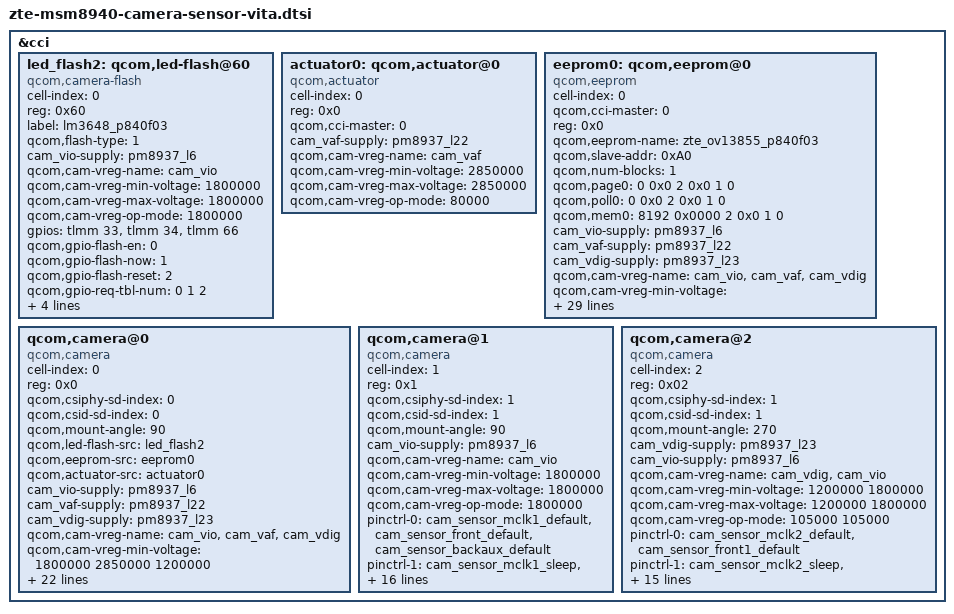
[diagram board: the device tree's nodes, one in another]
/*
 * Copyright (c) 2015-2017, The Linux Foundation. All rights reserved.
 *
 * This program is free software; you can redistribute it and/or modify
 * it under the terms of the GNU General Public License version 2 and
 * only version 2 as published by the Free Software Foundation.
 *
 * This program is distributed in the hope that it will be useful,
 * but WITHOUT ANY WARRANTY; without even the implied warranty of
 * MERCHANTABILITY or FITNESS FOR A PARTICULAR PURPOSE.  See the
 * GNU General Public License for more details.
 */


&cci {
	led_flash2: qcom,led-flash@60{
		cell-index = <0>;
		compatible = "qcom,camera-flash";
		reg = <0x60>;
		label = "lm3648_p840f03";
		qcom,flash-type = <1>;
		cam_vio-supply = <&pm8937_l6>;
		qcom,cam-vreg-name = "cam_vio";
		qcom,cam-vreg-min-voltage = <1800000>;
		qcom,cam-vreg-max-voltage = <1800000>;
		qcom,cam-vreg-op-mode = <1800000>;
		gpios = <&tlmm 33 0>,
			<&tlmm 34 0>,
			<&tlmm 66 0>;
		qcom,gpio-flash-en = <0>;
		qcom,gpio-flash-now = <1>;
		qcom,gpio-flash-reset = <2>;
		qcom,gpio-req-tbl-num = <0 1 2>;
		qcom,gpio-req-tbl-flags = <0 0 0>;
		qcom,gpio-req-tbl-label = "FLASH_EN",
			"FLASH_NOW",
			"FLASH_RESET";
		qcom,cci-master = <0>;
	};
	actuator0: qcom,actuator@0 {
		cell-index = <0>;
		reg = <0x0>;
		compatible = "qcom,actuator";
		qcom,cci-master = <0>;
		cam_vaf-supply = <&pm8937_l22>;
		qcom,cam-vreg-name = "cam_vaf";
		qcom,cam-vreg-min-voltage = <2850000>;
		qcom,cam-vreg-max-voltage = <2850000>;
		qcom,cam-vreg-op-mode = <80000>;
	};
	eeprom0: qcom,eeprom@0 {
		cell-index = <0>;
		qcom,cci-master = <0>;
		reg = <0x0>;
		qcom,eeprom-name = "zte_ov13855_p840f03";
		compatible = "qcom,eeprom";
		qcom,slave-addr = <0xA0>;
		qcom,num-blocks = <1>;
		qcom,page0 = <0 0x0 2 0x0 1 0>;
		qcom,poll0 = <0 0x0 2 0x0 1 0>;
		qcom,mem0 = <8192 0x0000 2 0x0 1 0>;
		cam_vio-supply = <&pm8937_l6>;
		cam_vaf-supply = <&pm8937_l22>;
		cam_vdig-supply = <&pm8937_l23>;
		qcom,cam-vreg-name = "cam_vio", "cam_vaf","cam_vdig";
		qcom,cam-vreg-min-voltage = <1800000 2850000 1200000>;
		qcom,cam-vreg-max-voltage = <1800000 2850000 1200000>;
		qcom,cam-vreg-op-mode = <80000 80000 80000>;
		pinctrl-names = "cam_default", "cam_suspend";
		pinctrl-0 = <&cam_sensor_mclk0_default
				&cam_sensor_rear_default &cam_sensor_rear_vana>;
		pinctrl-1 = <&cam_sensor_mclk0_sleep &cam_sensor_rear_sleep &cam_sensor_rear_vana_sleep>;
		gpios = <&tlmm 26 0>,
			<&tlmm 36 0>,
			<&tlmm 132 0>;
		qcom,gpio-reset = <1>;
		qcom,gpio-vana = <2>;
		qcom,gpio-req-tbl-num = <0 1 2 >;
		qcom,gpio-req-tbl-flags = <1 0 0 >;
		qcom,gpio-req-tbl-label = "CAMIF_MCLK0",
			"CAM_RESET0",
			"CAM_VANA";
		qcom,cam-power-seq-type = "sensor_gpio","sensor_vreg","sensor_gpio",
			"sensor_vreg","sensor_vreg","sensor_gpio","sensor_clk";
		qcom,cam-power-seq-val = "sensor_gpio_reset","cam_vio","sensor_gpio_vana",
			"cam_vdig","cam_vaf","sensor_gpio_reset","sensor_cam_mclk";
		qcom,cam-power-seq-cfg-val = <0 0 1 0 0 1  24000000>;
		qcom,cam-power-seq-delay = <0 0 0 0 0 5 5>;
		status = "ok";
		clocks = <&clock_gcc clk_mclk0_clk_src>,
				<&clock_gcc clk_gcc_camss_mclk0_clk>;
		clock-names = "cam_src_clk", "cam_clk";
		qcom,clock-rates = <24000000 0>;
	};
    /*Rear Camera*/
	qcom,camera@0 {
		cell-index = <0>;
		compatible = "qcom,camera";
		reg = <0x0>;
		qcom,csiphy-sd-index = <0>;
		qcom,csid-sd-index = <0>;
		qcom,mount-angle = <90>;
		qcom,led-flash-src = <&led_flash2>;
		qcom,eeprom-src = <&eeprom0>;
		qcom,actuator-src = <&actuator0>;
		cam_vio-supply = <&pm8937_l6>;
		cam_vaf-supply = <&pm8937_l22>;
		cam_vdig-supply = <&pm8937_l23>;
		qcom,cam-vreg-name = "cam_vio", "cam_vaf","cam_vdig";
		qcom,cam-vreg-min-voltage = <1800000 2850000 1200000>;
		qcom,cam-vreg-max-voltage = <1800000 2850000 1200000>;
		qcom,cam-vreg-op-mode = <80000 80000 80000>;
		pinctrl-names = "cam_default", "cam_suspend";
		pinctrl-0 = <&cam_sensor_mclk0_default
				&cam_sensor_rear_default &cam_sensor_rear_vana>;
		pinctrl-1 = <&cam_sensor_mclk0_sleep &cam_sensor_rear_sleep &cam_sensor_rear_vana_sleep>;
		gpios = <&tlmm 26 0>,
			<&tlmm 36 0>,
			<&tlmm 132 0>;
		qcom,gpio-reset = <1>;
		qcom,gpio-vana = <2>;
		qcom,gpio-req-tbl-num = <0 1 2 >;
		qcom,gpio-req-tbl-flags = <1 0 0 >;
		qcom,gpio-req-tbl-label = "CAMIF_MCLK0",
			"CAM_RESET0",
			"CAM_VANA-li";
		qcom,sensor-position = <0>;
		qcom,sensor-mode = <0>;
		qcom,cci-master = <0>;
		status = "ok";
		clocks = <&clock_gcc clk_mclk0_clk_src>,
				<&clock_gcc clk_gcc_camss_mclk0_clk>;
		clock-names = "cam_src_clk", "cam_clk";
		qcom,clock-rates = <24000000 0>;
	};
    /* depth Camera*/
	qcom,camera@1 {
		cell-index = <1>;
		compatible = "qcom,camera";
		reg = <0x1>;
		qcom,csiphy-sd-index = <1>;
		qcom,csid-sd-index = <1>;
		qcom,mount-angle = <90>;
		//cam_vdig-supply = <&pm8937_l6>;
		//qcom,actuator-src = <&actuator2>;
		//qcom,eeprom-src = <&eeprom2>;
		//cam_vdig-supply = <&pm8937_l23>;
		cam_vio-supply = <&pm8937_l6>;
		qcom,cam-vreg-name = "cam_vio";
		qcom,cam-vreg-min-voltage = <1800000>;
		qcom,cam-vreg-max-voltage = <1800000>;
		qcom,cam-vreg-op-mode = <1800000>;
		pinctrl-names = "cam_default", "cam_suspend";
		pinctrl-0 = <&cam_sensor_mclk1_default
				&cam_sensor_front_default &cam_sensor_backaux_default>;
		pinctrl-1 = <&cam_sensor_mclk1_sleep
				&cam_sensor_front_sleep &cam_sensor_backaux_sleep>;
		gpios = <&tlmm 27 0>,
			<&tlmm 38 0>,
			<&tlmm 50 0>,
			<&tlmm 99 0>;
		qcom,gpio-reset = <1>;
		qcom,gpio-standby = <2>;
		qcom,gpio-vana = <3>;
		qcom,gpio-req-tbl-num = <0 1 2 3>;
		qcom,gpio-req-tbl-flags = <1 0 0 0>;
		qcom,gpio-req-tbl-label = "CAMIF_MCLK1",
			"CAM_RESET1",
			"CAM_STANDBY1",
			"CAM_VANA1";
		qcom,sensor-position = <2>;
		qcom,sensor-mode = <1>;
		qcom,cci-master = <1>;
		clocks = <&clock_gcc clk_mclk1_clk_src>,
				<&clock_gcc clk_gcc_camss_mclk1_clk>;
		clock-names = "cam_src_clk", "cam_clk";
		qcom,clock-rates = <24000000 0>;
	};
	/* Front Camera*/
	qcom,camera@2 {
		cell-index = <2>;
		compatible = "qcom,camera";
		reg = <0x02>;
		qcom,csiphy-sd-index = <1>;
		qcom,csid-sd-index = <1>;
		qcom,mount-angle = <270>;
		//qcom,led-flash-src = <&led_flash1>;
		//qcom,eeprom-src = <&eeprom2>;
		cam_vdig-supply = <&pm8937_l23>;
		cam_vio-supply = <&pm8937_l6>;
		qcom,cam-vreg-name = "cam_vdig", "cam_vio";
		qcom,cam-vreg-min-voltage = <1200000 1800000>;
		qcom,cam-vreg-max-voltage = <1200000 1800000>;
		qcom,cam-vreg-op-mode = <105000 105000>;
		//qcom,gpio-no-mux = <0>;
		pinctrl-names = "cam_default", "cam_suspend";
		pinctrl-0 = <&cam_sensor_mclk2_default
				&cam_sensor_front1_default>;
		pinctrl-1 = <&cam_sensor_mclk2_sleep
				&cam_sensor_front1_sleep>;
		gpios = <&tlmm 28 0>,
			<&tlmm 40 0>,
			<&tlmm 39 0>,
			<&tlmm 13 0>;
		qcom,gpio-reset = <1>;
		qcom,gpio-standby = <2>;
		qcom,gpio-vana = <3>;
		qcom,gpio-req-tbl-num = <0 1 2 3>;
		qcom,gpio-req-tbl-flags = <1 0 0 0>;
		qcom,gpio-req-tbl-label = "CAMIF_MCLK2",
					  "CAM_RESET2",
					  "CAM_STANDBY2",
					  "CAM_VANA";
		qcom,sensor-position = <1>;
		qcom,sensor-mode = <0>;
		qcom,cci-master = <0>;
		status = "ok";
		clocks = <&clock_gcc clk_mclk2_clk_src>,
			<&clock_gcc clk_gcc_camss_mclk2_clk>;
		clock-names = "cam_src_clk", "cam_clk";
		qcom,clock-rates = <24000000 0>;
	};
};
